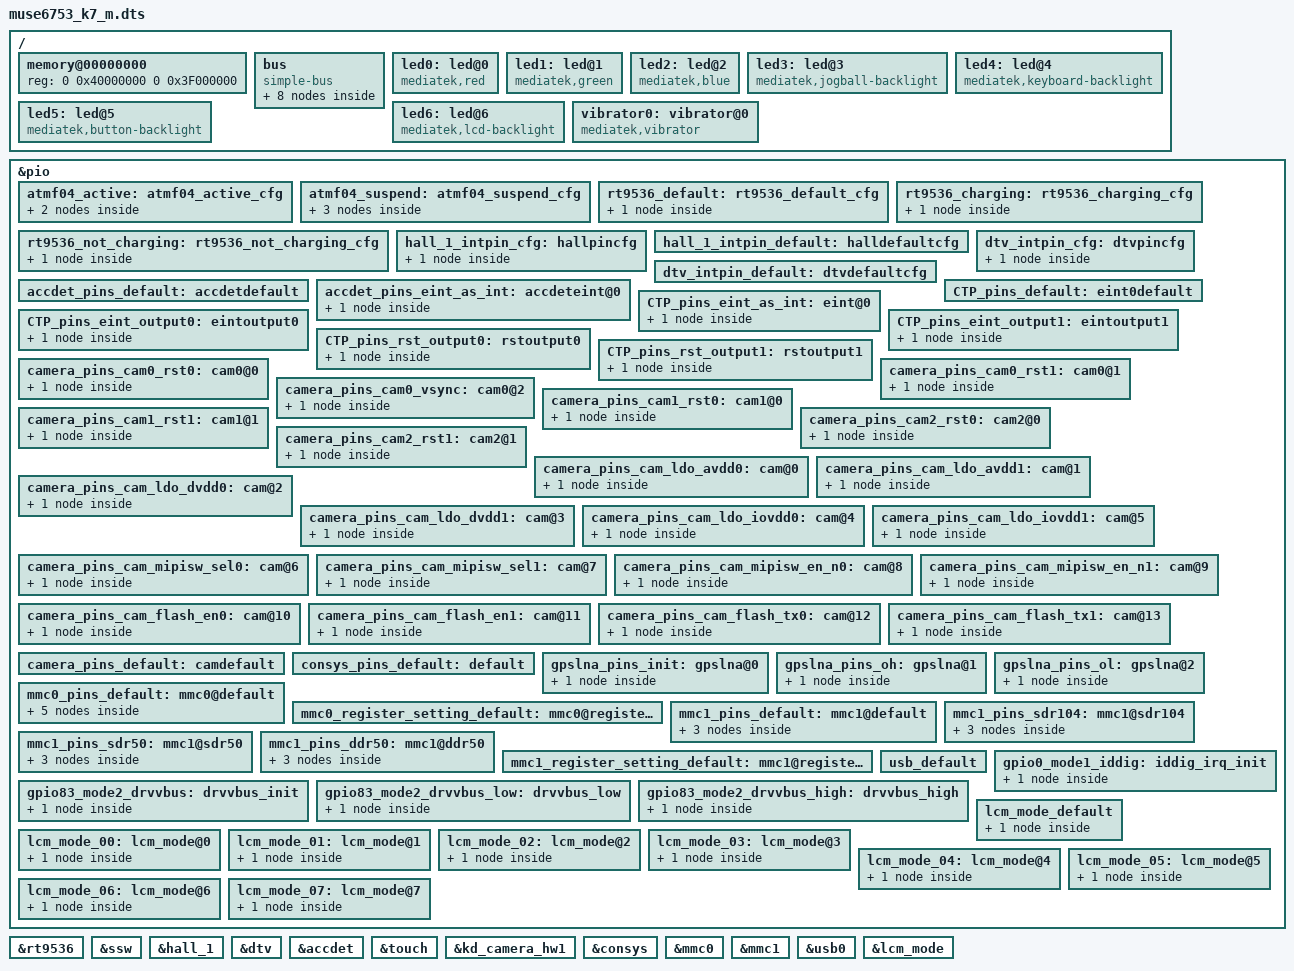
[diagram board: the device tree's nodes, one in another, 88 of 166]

/dts-v1/;

#include "mt6753.dtsi"
#include <dt-bindings/lcm/r63417_fhd_dsi_cmd_truly_nt50358.dtsi>

/ {
memory@00000000 {
		device_type = "memory";
		reg = <0 0x40000000 0 0x3F000000>;
	};

	bus {
		compatible = "simple-bus";
		#address-cells = <1>;
		#size-cells = <1>;
		ranges = <0 0 0 0xffffffff>;

		MTKFB@5e200000 {
			compatible = "mediatek,MTKFB";
			reg = <0x7F000000 0x1000000>;
		};

		i2c@11008000 {
			synaptics_s3320@20 {
				status = "ok";
				compatible = "unified_driver_ver3,s3320";
				reg = <0x20>;
			};
		};
		i2c@11009000 {
			adsemicon_atmf04@5a {
				compatible = "adsemicon,atmf04";
				status = "ok";
				reg = <0x5a>;
				interrupt-parent = <&eintc>;
				interrupts = <126 IRQ_TYPE_EDGE_BOTH>,
					     <127 IRQ_TYPE_EDGE_BOTH>;
				debounce = <10 0>;
				def_speed = <100>;
				Adsemicon,fw_name = "atmf04/ATMF04_LGK7T_012.fw";

				pinctrl-names = "touch_key_active", "touch_key_suspend";
				pinctrl-0 = <&atmf04_active>;
				pinctrl-1 = <&atmf04_suspend>;
			};
		};

		i2c@1100f000{
/*			accel_stm@6B{
				compatible = "mediatek,lsm6ds3_accel";
				reg = <0x6B>;
				status = "ok";
				revision = "rev_a...";
				i2c_num = <3>;
				i2c_addr=<0x6B 0 0 0>;
				direction = <0>;
				power_id= <0xffff>;
				power_vol= <0>;
				firlen = <0>;
				is_batch_supported = <0>;
			};
			gyro_stm@6B{
				compatible = "mediatek,lsm6ds3_gyro";
				reg = <0x6B>;
				status = "ok";
				revision = "rev_a...";
				i2c_num = <3>;
				i2c_addr=<0x6B 0 0 0>;
				direction = <0>;
				power_id= <0xffff>;
				power_vol= <0>;
				firlen = <0>;
				is_batch_supported = <0>;
			};*/

			alsps@53{
				compatible = "mediatek,alsps";
				reg = <0x39>;
				status = "okay";
				i2c_num				= <3>;
				i2c_addr				= <0x39 0 0 0>;
				polling_mode_ps			= <0>;
				polling_mode_als		= <0>;
				power_id				= <0xffff>;
				power_vol				= <0>;
				als_level = <0 328 861 1377 3125 7721 7767 12621 23062 28430 33274 47116 57694 57694 65535>;
				als_value = <0 133 304 502 1004 2005 3058 5005 8008 10010 12000 16000 20000 20000 20000 20000>;
				far_offset	=  <500>;
				near_offset		=  <300>;
				crosstalk_max		=  <650>;
				ppcount			=  <0x08>;
				ps_led_current	=	<0xe4>;/* 4:50mA  5:75mA  6:100mA */
				als_up_thres	=	<4>;
				als_low_thres	=	<4>;
				als_ga	=	<12>;
				als_coe_b	=	<12>;
				als_coe_c	=	<12>;
				is_batch_supported_ps	= <0>;
				is_batch_supported_als	= <0>;
				};

			mag_akm09916@c{
				compatible = "mediatek,akm09916";
				status= "ok";
				reg=<0x0c>;
				i2c_num = <3>;
				i2c_addr=<0x0c 0 0 0>;
				direction = <7>;
				power_id= <0xffff>;
				is_batch_supported = <0>;
			};
		};
	};
	led0:led@0 {
		compatible = "mediatek,red";
		led_mode = <3>;
		data = <1>;
		pwm_config = <0 0 0 0 0>;
	};
	led1:led@1 {
		compatible = "mediatek,green";
		led_mode = <0>;
		data = <1>;
		pwm_config = <0 0 0 0 0>;
	};
	led2:led@2 {
		compatible = "mediatek,blue";
		led_mode = <0>;
		data = <1>;
		pwm_config = <0 0 0 0 0>;
	};
	led3:led@3 {
		compatible = "mediatek,jogball-backlight";
		led_mode = <0>;
		data = <1>;
		pwm_config = <0 0 0 0 0>;
	};
	led4:led@4 {
		compatible = "mediatek,keyboard-backlight";
		led_mode = <0>;
		data = <1>;
		pwm_config = <0 0 0 0 0>;
	};
	led5:led@5 {
		compatible = "mediatek,button-backlight";
		led_mode = <3>;
		data = <2>;
		pwm_config = <0 0 0 0 0>;
	};
	led6:led@6 {
		compatible = "mediatek,lcd-backlight";
		led_mode = <4>;
		data = <1>;
		pwm_config = <0 0 0 0 0>;
	};
	vibrator0:vibrator@0 {
		compatible = "mediatek,vibrator";
		vib_timer = <25>;
		vib_limit = <9>;
		vib_vol= <5>;
	};
};

/* touch key */
&pio {
	atmf04_active: atmf04_active_cfg {
		menu_set {
			pins = <PINMUX_GPIO126__FUNC_GPIO126>;
			input-enable;
		};
		back_set {
			pins = <PINMUX_GPIO127__FUNC_GPIO127>;
			input-enable;
		};
	};

	atmf04_suspend: atmf04_suspend_cfg {
		en_set{
			pins = <PINMUX_GPIO125__FUNC_GPIO125>;
			output-high;
		};
		menu_set {
			pins = <PINMUX_GPIO126__FUNC_GPIO126>;
			input-disable;
		};
		back_set {
			pins = <PINMUX_GPIO127__FUNC_GPIO127>;
			input-disable;
		};
	};
};

/* charger ic */
&rt9536 {
	status = "okay";
	pinctrl-names = "default", "charging", "not_charging";
	pinctrl-0 = <&rt9536_default>;
	pinctrl-1 = <&rt9536_charging>;
	pinctrl-2 = <&rt9536_not_charging>;
	en_set = <8>;
	chgsb = <9>;
};
&pio {
	rt9536_default: rt9536_default_cfg {
		chgsb {
			pins = <PINMUX_GPIO9__FUNC_GPIO9>;
			input-enable;
		};
	};

	rt9536_charging: rt9536_charging_cfg {
		en_set {
			pins = <PINMUX_GPIO8__FUNC_GPIO8>;
			output-low;
		};
	};
	rt9536_not_charging: rt9536_not_charging_cfg {
		en_set {
			pins = <PINMUX_GPIO8__FUNC_GPIO8>;
			output-high;
		};
	};
};

&ssw {
	pinctrl-1 = <>;
	pinctrl-2 = <>;
};

&hall_1 {
	pinctrl-names = "pin_default", "pin_cfg";
	pinctrl-0 = <&hall_1_intpin_default>;
	pinctrl-1 = <&hall_1_intpin_cfg>;
	status = "okay";
};

&pio {
	hall_1_intpin_cfg: hallpincfg {
		pins_cmd_dat {
			pins = <PINMUX_GPIO3__FUNC_GPIO3>;
			slew-rate = <0>;
			bias-disable;
			input-enable;
		};
	};

	hall_1_intpin_default: halldefaultcfg {

	};
};

&dtv {
	pinctrl-names = "pin_default", "pin_cfg";
	pinctrl-0 = <&dtv_intpin_default>;
	pinctrl-1 = <&dtv_intpin_cfg>;
	status = "okay";
};

&pio {
	dtv_intpin_cfg: dtvpincfg {
		pins_cmd_dat {
			pins = <PINMUX_GPIO109__FUNC_GPIO109>;
			slew-rate = <0>;
			bias-pull-down = <00>;
		};
	};

	dtv_intpin_default: dtvdefaultcfg {

	};
};

/* sensor end */

&accdet {
	accdet-mic-vol = <7>;
	headset-mode-setting = <0x500 0x500 1 0x1f0 0x800 0x800 0x20>;
	accdet-plugout-debounce = <20>;
	/*1:ACC mode, 2:low cost without in bias, 6:low cost with in bias*/
	accdet-mic-mode = <1>;
	/*0--MD_MAX--UP_MAX--DW_MAX*/
	headset-three-key-threshold = <0 80 180 500>;
	/*0--MD_MAX--VOICE_MAX--UP_MAX--DW_MAX*/
	headset-four-key-threshold = <0 80 105 180 500>;
	/* ACCDET GPIO standardization ACC mode use */
	pinctrl-names = "default", "state_eint_as_int";
	pinctrl-0 = <&accdet_pins_default>;
	pinctrl-1 = <&accdet_pins_eint_as_int>;
	status = "okay";
};
&pio {
	accdet_pins_default: accdetdefault {
	};
	accdet_pins_eint_as_int: accdeteint@0 {
		pins_cmd_dat {
			pins = <PINMUX_GPIO7__FUNC_GPIO7>;
			slew-rate = <0>;
			bias-disable;
		};
	};
};
&touch {
	tpd-resolution = <1080 1920>;
	use-tpd-button = <0>;
	tpd-key-num = <3>;
	tpd-key-local= <139 172 158 0>;
	tpd-key-dim-local = <90 883 100 40 230 883 100 40 370 883 100 40 0 0 0 0>;
	tpd-max-touch-num = <5>;
	tpd-filter-enable = <1>;
	tpd-filter-pixel-density = <186>;
	tpd-filter-custom-prameters = <0 0 0 0 0 0 0 0 0 0 0 0>;
	tpd-filter-custom-speed = <0 0 0>;
	pinctrl-names = "default", "state_eint_as_int", "state_eint_output0", "state_eint_output1",
		"state_rst_output0", "state_rst_output1";
	pinctrl-0 = <&CTP_pins_default>;
	pinctrl-1 = <&CTP_pins_eint_as_int>;
	pinctrl-2 = <&CTP_pins_eint_output0>;
	pinctrl-3 = <&CTP_pins_eint_output1>;
	pinctrl-4 = <&CTP_pins_rst_output0>;
	pinctrl-5 = <&CTP_pins_rst_output1>;
	status = "okay";
};
&pio {
	CTP_pins_default: eint0default {
	};
	CTP_pins_eint_as_int: eint@0 {
		pins_cmd_dat {
			pins = <PINMUX_GPIO10__FUNC_GPIO10>;
			slew-rate = <0>;
			bias-disable;
		};
	};
	CTP_pins_eint_output0: eintoutput0 {
		pins_cmd_dat {
			pins = <PINMUX_GPIO10__FUNC_GPIO10>;
			slew-rate = <1>;
			output-low;
		};
	};
	CTP_pins_eint_output1: eintoutput1 {
		pins_cmd_dat {
			pins = <PINMUX_GPIO10__FUNC_GPIO10>;
			slew-rate = <1>;
			output-high;
		};
	};
	CTP_pins_rst_output0: rstoutput0 {
		pins_cmd_dat {
			pins = <PINMUX_GPIO62__FUNC_GPIO62>;
			slew-rate = <1>;
			output-low;
		};
	};
	CTP_pins_rst_output1: rstoutput1 {
		pins_cmd_dat {
			pins = <PINMUX_GPIO62__FUNC_GPIO62>;
			slew-rate = <1>;
			output-high;
		};
	};
};
/* TOUCH end */

/* CAMERA GPIO standardization */
&pio {
	camera_pins_cam0_rst0: cam0@0 {
		pins_cmd_dat {
			pins = <PINMUX_GPIO44__FUNC_GPIO44>;/*GPIO_CAMERA_CMRST_PIN*/
			slew-rate = <1>; /*direction 0:in, 1:out*/
			output-low;/*direction out used only. output_low or high*/
		};
	};
	camera_pins_cam0_rst1: cam0@1 {
		pins_cmd_dat {
			pins = <PINMUX_GPIO44__FUNC_GPIO44>;/*GPIO_CAMERA_CMRST_PIN*/
			slew-rate = <1>;
			output-high;
		};
	};
	camera_pins_cam0_vsync: cam0@2 {
		pins_cmd_dat {
			pins = <PINMUX_GPIO106__FUNC_GPIO106>;
			slew-rate = <0>;
			bias-disable;
		};
	};
	camera_pins_cam1_rst0: cam1@0 {
		pins_cmd_dat {
			pins = <PINMUX_GPIO11__FUNC_GPIO11>;/*GPIO_CAMERA_CMRST1_PIN*/
			slew-rate = <1>; /*direction 0:in, 1:out*/
			output-low;/*direction out used only. output_low or high*/
		};
	};
	camera_pins_cam1_rst1: cam1@1 {
		pins_cmd_dat {
			pins = <PINMUX_GPIO11__FUNC_GPIO11>;/*GPIO_CAMERA_CMRST1_PIN*/
			slew-rate = <1>;
			output-high;
		};
	};
	camera_pins_cam2_rst0: cam2@0 {
		pins_cmd_dat {
			pins = <PINMUX_GPIO83__FUNC_GPIO83>;/*GPIO_CAMERA_CMRST2_PIN*/
			slew-rate = <1>; /*direction 0:in, 1:out*/
			output-low;/*direction out used only. output_low or high*/
		};
	};
	camera_pins_cam2_rst1: cam2@1 {
		pins_cmd_dat {
			pins = <PINMUX_GPIO83__FUNC_GPIO83>;/*GPIO_CAMERA_CMRST2_PIN*/
			slew-rate = <1>;
			output-high;
		};
	};
	camera_pins_cam_ldo_avdd0: cam@0 {
		pins_cmd_dat {
			pins = <PINMUX_GPIO76__FUNC_GPIO76>;/*AVDD*/
			slew-rate = <1>;
			output-low;
		};
	};
	camera_pins_cam_ldo_avdd1: cam@1 {
		pins_cmd_dat {
			pins = <PINMUX_GPIO76__FUNC_GPIO76>;/*AVDD*/
			slew-rate = <1>;
			output-high;
		};
	};
	camera_pins_cam_ldo_dvdd0: cam@2 {
		pins_cmd_dat {
			pins = <PINMUX_GPIO77__FUNC_GPIO77>;/*DVDD*/
			slew-rate = <1>;
			output-low;
		};
	};
	camera_pins_cam_ldo_dvdd1: cam@3 {
		pins_cmd_dat {
			pins = <PINMUX_GPIO77__FUNC_GPIO77>;/*DVDD*/
			slew-rate = <1>;
			output-high;
		};
	};
	camera_pins_cam_ldo_iovdd0: cam@4 {
		pins_cmd_dat {
			pins = <PINMUX_GPIO64__FUNC_GPIO64>;/*IOVDD*/
			slew-rate = <1>;
			output-low;
		};
	};
	camera_pins_cam_ldo_iovdd1: cam@5 {
		pins_cmd_dat {
			pins = <PINMUX_GPIO64__FUNC_GPIO64>;/*IOVDD*/
			slew-rate = <1>;
			output-high;
		};
	};
	camera_pins_cam_mipisw_sel0: cam@6 {
		pins_cmd_dat {
			pins = <PINMUX_GPIO63__FUNC_GPIO63>;/*MIPI_SWITCH_SEL*/
			slew-rate = <1>;
			output-low;
		};
	};
	camera_pins_cam_mipisw_sel1: cam@7 {
		pins_cmd_dat {
			pins = <PINMUX_GPIO63__FUNC_GPIO63>;/*MIPI_SWITCH_SEL*/
			slew-rate = <1>;
			output-high;
		};
	};
	camera_pins_cam_mipisw_en_n0: cam@8 {
		pins_cmd_dat {
			pins = <PINMUX_GPIO19__FUNC_GPIO19>;/*MIPI_SWITCH_EN_N*/
			slew-rate = <1>;
			output-low;
		};
	};
	camera_pins_cam_mipisw_en_n1: cam@9 {
		pins_cmd_dat {
			pins = <PINMUX_GPIO19__FUNC_GPIO19>;/*MIPI_SWITCH_EN_N*/
			slew-rate = <1>;
			output-high;
		};
	};
	camera_pins_cam_flash_en0: cam@10 {
		pins_cmd_dat {
			pins = <PINMUX_GPIO42__FUNC_GPIO42>;/*FLASH EN*/
			slew-rate = <1>;
			output-low;
		};
	};
	camera_pins_cam_flash_en1: cam@11 {
		pins_cmd_dat {
			pins = <PINMUX_GPIO42__FUNC_GPIO42>;/*FLASH EN*/
			slew-rate = <1>;
			output-high;
		};
	};
	camera_pins_cam_flash_tx0: cam@12 {
		pins_cmd_dat {
			pins = <PINMUX_GPIO43__FUNC_GPIO43>;/*FLASH TX*/
			slew-rate = <1>;
			output-low;
		};
	};
	camera_pins_cam_flash_tx1: cam@13 {
		pins_cmd_dat {
			pins = <PINMUX_GPIO43__FUNC_GPIO43>;/*FLASH TX*/
			slew-rate = <1>;
			output-high;
		};
	};
	camera_pins_default: camdefault {

	};
};

&kd_camera_hw1 {
	pinctrl-names = "default", "cam0_rst0", "cam0_rst1", "cam0_vsync",
	"cam1_rst0", "cam1_rst1", "cam2_rst0", "cam2_rst1",
	"cam_ldo_avdd0", "cam_ldo_avdd1", "cam_ldo_dvdd0", "cam_ldo_dvdd1",
	"cam_ldo_iovdd0", "cam_ldo_iovdd1",
	"cam_mipisw_sel0", "cam_mipisw_sel1", "cam_mipisw_en_n0", "cam_mipisw_en_n1",
	"cam_flash_en0", "cam_flash_en1", "cam_flash_tx0", "cam_flash_tx1";
	pinctrl-0 = <&camera_pins_default>;
	pinctrl-1 = <&camera_pins_cam0_rst0>;
	pinctrl-2 = <&camera_pins_cam0_rst1>;
	pinctrl-3 = <&camera_pins_cam0_vsync>;
	pinctrl-4 = <&camera_pins_cam1_rst0>;
	pinctrl-5 = <&camera_pins_cam1_rst1>;
	pinctrl-6 = <&camera_pins_cam2_rst0>;
	pinctrl-7 = <&camera_pins_cam2_rst1>;
	pinctrl-8 = <&camera_pins_cam_ldo_avdd0>;
	pinctrl-9 = <&camera_pins_cam_ldo_avdd1>;
	pinctrl-10 = <&camera_pins_cam_ldo_dvdd0>;
	pinctrl-11 = <&camera_pins_cam_ldo_dvdd1>;
	pinctrl-12 = <&camera_pins_cam_ldo_iovdd0>;
	pinctrl-13 = <&camera_pins_cam_ldo_iovdd1>;
	pinctrl-14 = <&camera_pins_cam_mipisw_sel0>;
	pinctrl-15 = <&camera_pins_cam_mipisw_sel1>;
	pinctrl-16 = <&camera_pins_cam_mipisw_en_n0>;
	pinctrl-17 = <&camera_pins_cam_mipisw_en_n1>;
	pinctrl-18 = <&camera_pins_cam_flash_en0>;
	pinctrl-19 = <&camera_pins_cam_flash_en1>;
	pinctrl-20 = <&camera_pins_cam_flash_tx0>;
	pinctrl-21 = <&camera_pins_cam_flash_tx1>;
	vtcxo_1-supply = <&mt_pmic_vtcxo_1_ldo_reg>;
	vrf18_1-supply = <&mt_pmic_vrf18_1_ldo_reg>;
	vgp1-supply = <&mt_pmic_vgp1_ldo_reg>;
	status = "okay";

};
/* CAMERA GPIO end */

/* CONSYS GPIO standardization */
&pio {
	consys_pins_default: default {

	};

	gpslna_pins_init: gpslna@0 {

	    pins_cmd_dat {
			pins = <PINMUX_GPIO79__FUNC_GPIO79>;
			slew-rate = <0>;
			bias-disable;
			output-low;
		};
	};

	gpslna_pins_oh: gpslna@1 {

	    pins_cmd_dat {
			pins = <PINMUX_GPIO79__FUNC_GPIO79>;
			slew-rate = <1>;
			output-high;
		};
	};

	gpslna_pins_ol: gpslna@2 {

	    pins_cmd_dat {
			pins = <PINMUX_GPIO79__FUNC_GPIO79>;
			slew-rate = <1>;
			output-low;
		};
	};

};

&consys {
	pinctrl-names = "default", "gps_lna_state_init", "gps_lna_state_oh", "gps_lna_state_ol";
	pinctrl-0 = <&consys_pins_default>;
	pinctrl-1 = <&gpslna_pins_init>;
	pinctrl-2 = <&gpslna_pins_oh>;
	pinctrl-3 = <&gpslna_pins_ol>;
	status = "okay";

};
/* CONSYS end */
/* mmc start */
&mmc0 {
		clk_src = /bits/ 8 <MSDC50_CLKSRC_400MHZ>;
		bus-width = <8>;
		max-frequency = <200000000>;
		cap-mmc-highspeed;
		msdc-sys-suspend;
		mmc-ddr-1_8v;
		mmc-hs200-1_8v;
		mmc-hs400-1_8v;
		non-removable;
		pinctl = <&mmc0_pins_default>;
		register_setting = <&mmc0_register_setting_default>;
		host_function = /bits/ 8 <MSDC_EMMC>;
		bootable;
		status = "okay";
};

&mmc1 {
		clk_src = /bits/ 8 <MSDC30_CLKSRC_200MHZ>;
		bus-width = <4>;
		max-frequency = <200000000>;
		msdc-sys-suspend;
		cap-sd-highspeed;
		sd-uhs-sdr12;
		sd-uhs-sdr25;
		sd-uhs-sdr50;
		sd-uhs-sdr104;
		sd-uhs-ddr50;
		pinctl = <&mmc1_pins_default>;
		pinctl_sdr104 = <&mmc1_pins_sdr104>;
		pinctl_sdr50 = <&mmc1_pins_sdr50>;
		pinctl_ddr50 = <&mmc1_pins_ddr50>;
		register_setting = <&mmc1_register_setting_default>;
		host_function = /bits/ 8 <MSDC_SD>;
		cd_level = /bits/ 8 <MSDC_CD_HIGH>;
		cd-gpios = <&pio 1 0>;
		status = "okay";
};

&pio {
	mmc0_pins_default: mmc0@default {
			pins_cmd {
				drive-strength = /bits/ 8 <2>;
			};
			pins_dat {
				drive-strength = /bits/ 8 <2>;
			};
			pins_clk {
				drive-strength = /bits/ 8 <2>;
			};
			pins_rst {
				drive-strength = /bits/ 8 <2>;
			};
			pins_ds {
				drive-strength = /bits/ 8 <2>;
			};
	};

	mmc0_register_setting_default: mmc0@register_default {
		dat0rddly      = /bits/ 8 <0>;
		dat1rddly      = /bits/ 8 <0>;
		dat2rddly      = /bits/ 8 <0>;
		dat3rddly      = /bits/ 8 <0>;
		dat4rddly      = /bits/ 8 <0>;
		dat5rddly      = /bits/ 8 <0>;
		dat6rddly      = /bits/ 8 <0>;
		dat7rddly      = /bits/ 8 <0>;
		datwrddly      = /bits/ 8 <0>;
		cmdrrddly      = /bits/ 8 <0>;
		cmdrddly       = /bits/ 8 <0>;
		cmd_edge = /bits/ 8 <MSDC_SMPL_FALLING>;
		rdata_edge = /bits/ 8 <MSDC_SMPL_FALLING>;
		wdata_edge = /bits/ 8 <MSDC_SMPL_FALLING>;

		ett-hs200-cells = <12>;
		ett-hs200-default = <OFFSET_MSDC_PATCH_BIT0	MSDC_PB0_INT_DAT_LATCH_CK_SEL 0x0
			OFFSET_MSDC_PATCH_BIT0	MSDC_PB0_CKGEN_MSDC_DLY_SEL   0x0
			OFFSET_MSDC_PATCH_BIT1	MSDC_PB1_CMD_RSP_TA_CNTR      0x1
			OFFSET_MSDC_IOCON		MSDC_IOCON_RSPL               0x0
			OFFSET_MSDC_PAD_TUNE0	MSDC_PAD_TUNE0_CMDRDLY        0x7
			OFFSET_MSDC_PAD_TUNE0	MSDC_PAD_TUNE0_CMDRRDLY       0xb
			OFFSET_MSDC_PATCH_BIT1		MSDC_PB1_WRDAT_CRCS_TA_CNTR   0x1
			OFFSET_MSDC_PAD_TUNE0	MSDC_PAD_TUNE0_DATWRDLY       0xb
			OFFSET_MSDC_IOCON			MSDC_IOCON_W_D0SPL            0x0
			OFFSET_MSDC_DAT_RDDLY0		MSDC_DAT_RDDLY0_D0            0x7
			OFFSET_MSDC_PAD_TUNE0	MSDC_PAD_TUNE0_DATRRDLY       0x9
			OFFSET_MSDC_IOCON		MSDC_IOCON_R_D_SMPL           0x0>;

		ett-hs400-cells = <8>;
		ett-hs400-default = <OFFSET_MSDC_PATCH_BIT0	MSDC_PB0_INT_DAT_LATCH_CK_SEL	0x0
			OFFSET_MSDC_PATCH_BIT0		MSDC_PB0_CKGEN_MSDC_DLY_SEL		0x0
			OFFSET_EMMC50_PAD_DS_TUNE	MSDC_EMMC50_PAD_DS_TUNE_DLY1	0x2
			OFFSET_EMMC50_PAD_DS_TUNE	MSDC_EMMC50_PAD_DS_TUNE_DLY3	0x10
			OFFSET_MSDC_PATCH_BIT1			MSDC_PB1_CMD_RSP_TA_CNTR	0x1
			OFFSET_MSDC_IOCON		MSDC_IOCON_RSPL				0x0
			OFFSET_MSDC_PAD_TUNE0			MSDC_PAD_TUNE0_CMDRDLY		0x6
			OFFSET_MSDC_PAD_TUNE0		MSDC_PAD_TUNE0_CMDRRDLY		0x6>;
	};

	mmc1_pins_default: mmc1@default {
			pins_cmd {
				drive-strength = /bits/ 8 <3>;
			};
			pins_dat {
				drive-strength = /bits/ 8 <3>;
			};
			pins_clk {
				drive-strength = /bits/ 8 <3>;
			};
	};

	mmc1_pins_sdr104: mmc1@sdr104 {
			pins_cmd {
				drive-strength = /bits/ 8 <2>;
			};
			pins_dat {
				drive-strength = /bits/ 8 <2>;
			};
			pins_clk {
				drive-strength = /bits/ 8 <3>;
			};
	};

	mmc1_pins_sdr50: mmc1@sdr50 {
			pins_cmd {
				drive-strength = /bits/ 8 <2>;
			};
			pins_dat {
				drive-strength = /bits/ 8 <2>;
			};
			pins_clk {
				drive-strength = /bits/ 8 <3>;
			};
	};

	mmc1_pins_ddr50: mmc1@ddr50 {
			pins_cmd {
				drive-strength = /bits/ 8 <2>;
			};
			pins_dat {
				drive-strength = /bits/ 8 <2>;
			};
			pins_clk {
				drive-strength = /bits/ 8 <3>;
			};
	};

	mmc1_register_setting_default: mmc1@register_default {
				dat0rddly      = /bits/ 8 <0>;
				dat1rddly      = /bits/ 8 <0>;
				dat2rddly      = /bits/ 8 <0>;
				dat3rddly      = /bits/ 8 <0>;
				datwrddly      = /bits/ 8 <0>;
				cmdrrddly      = /bits/ 8 <0>;
				cmdrddly       = /bits/ 8 <0>;
				cmd_edge = /bits/ 8 <MSDC_SMPL_FALLING>;
				rdata_edge = /bits/ 8 <MSDC_SMPL_FALLING>;
				wdata_edge = /bits/ 8 <MSDC_SMPL_FALLING>;
	};
};
/* mmc end */

/* USB GPIO Kernal Standardization start */
&pio {
	usb_default: usb_default {
	};

	gpio0_mode1_iddig: iddig_irq_init {
		pins_cmd_dat {
			pins = <PINMUX_GPIO0__FUNC_IDDIG>;
			slew-rate = <0>;
			bias-pull-up = <00>;
		};
	};

	gpio83_mode2_drvvbus: drvvbus_init {
		pins_cmd_dat {
			pins = <PINMUX_GPIO83__FUNC_GPIO83>;
			slew-rate = <1>;
			bias-pull-down = <00>;
		};
	};

	gpio83_mode2_drvvbus_low: drvvbus_low {
		pins_cmd_dat {
			pins = <PINMUX_GPIO83__FUNC_GPIO83>;
			slew-rate = <1>;
			output-low;
			bias-pull-down = <00>;
		};
	};

	gpio83_mode2_drvvbus_high: drvvbus_high {
		pins_cmd_dat {
			pins = <PINMUX_GPIO83__FUNC_GPIO83>;
			slew-rate = <1>;
			output-high;
			bias-pull-down = <00>;
		};
	};
};

&usb0 {
	iddig_gpio = <0 1>;
	pinctrl-names = "usb_default", "iddig_irq_init", "drvvbus_init", "drvvbus_low", "drvvbus_high";
	pinctrl-0 = <&usb_default>;
	pinctrl-1 = <&gpio0_mode1_iddig>;
	pinctrl-2 = <&gpio83_mode2_drvvbus>;
	pinctrl-3 = <&gpio83_mode2_drvvbus_low>;
	pinctrl-4 = <&gpio83_mode2_drvvbus_high>;
	status = "okay";
};
/* USB GPIO Kernal Standardization end */

/* LCM GPIO Kernal Standardization start */
&pio {
	lcm_mode_default: lcm_mode_default {
		pins_cmd_dat {
			pins = <PINMUX_GPIO80__FUNC_GPIO80>;
		};
	};

	lcm_mode_00: lcm_mode@0 {
		pins_cmd_dat {
			pins = <PINMUX_GPIO80__FUNC_GPIO80>;
		};
	};

	lcm_mode_01: lcm_mode@1 {
		pins_cmd_dat {
			pins = <PINMUX_GPIO80__FUNC_I2S0_BCK>;
		};
	};

	lcm_mode_02: lcm_mode@2 {
		pins_cmd_dat {
			pins = <PINMUX_GPIO80__FUNC_PCM1_CLK_1>;
		};
	};

	lcm_mode_03: lcm_mode@3 {
		pins_cmd_dat {
			pins = <PINMUX_GPIO80__FUNC_I2S3_BCK>;
		};
	};

	lcm_mode_04: lcm_mode@4 {
		pins_cmd_dat {
			pins = <PINMUX_GPIO80__FUNC_I2S1_BCK>;
		};
	};

	lcm_mode_05: lcm_mode@5 {
		pins_cmd_dat {
			pins = <PINMUX_GPIO80__FUNC_PWM4>;
		};
	};

	lcm_mode_06: lcm_mode@6 {
		pins_cmd_dat {
			pins = <PINMUX_GPIO80__FUNC_I2S2_BCK>;
		};
	};

	lcm_mode_07: lcm_mode@7 {
		pins_cmd_dat {
			pins = <PINMUX_GPIO80__FUNC_DBG_MON_A28>;
		};
	};
};

&lcm_mode {
	pinctrl-names = "default", "lcm_mode_00", "lcm_mode_01", "lcm_mode_02", "lcm_mode_03", "lcm_mode_04",
	 "lcm_mode_05", "lcm_mode_06", "lcm_mode_07";
	pinctrl-0 = <&lcm_mode_default>;
	pinctrl-1 = <&lcm_mode_00>;
	pinctrl-2 = <&lcm_mode_01>;
	pinctrl-3 = <&lcm_mode_02>;
	pinctrl-4 = <&lcm_mode_03>;
	pinctrl-5 = <&lcm_mode_04>;
	pinctrl-6 = <&lcm_mode_05>;
	pinctrl-7 = <&lcm_mode_06>;
	pinctrl-8 = <&lcm_mode_07>;
	lcm_power_gpio = <&pio 80 0>;
	lcm_bl_gpio = <&pio 129 0>;
	status = "okay";
};
/* LCM GPIO Kernal Standardization end */
